# max32630 register map
Vendor: Maxim Integrated; Series: max3263x; File version: 1.2
CPU: CM4 r0p1, little endian, no MPU, FPU, 3 interrupt priority bits
Registers are 32-bit, read-write, reset 0x0 unless marked. A register's access mark holds for its fields unless they carry their own. Offsets are from the block's base; [hi:lo] are bit positions; {n}, {i} and the like mark numbered series; 'fields as' and 'values as' point back to an identical list.

## CLKMAN — System Clock Manager
Base 0x40000400
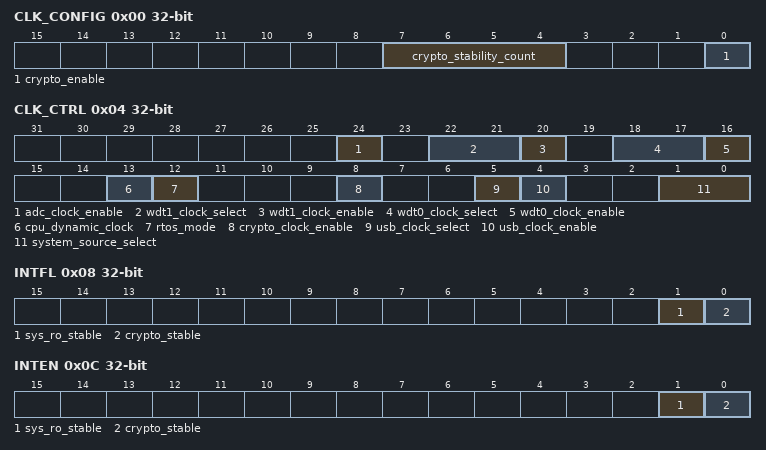
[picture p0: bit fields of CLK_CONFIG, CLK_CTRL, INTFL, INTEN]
0x00 CLK_CONFIG — System Clock Configuration
  [7:4] crypto_stability_count — Crypto Oscillator Stability Select
    0=2_EXP_8_CLOCKS (Clock is stable after 2^8 (256) clock cycles.); 1=2_EXP_9_CLOCKS (Clock is stable after 2^9 (512) clock cycles.); 2=2_EXP_10_CLOCKS (Clock is stable after 2^10 (1024) clock cycles.); 3=2_EXP_11_CLOCKS (Clock is stable after 2^11 (2048) clock cycles.); 4=2_EXP_12_CLOCKS (Clock is stable after 2^12 (4096) clock cycles.); 5=2_EXP_13_CLOCKS (Clock is stable after 2^13 (8192) clock cycles.); 6=2_EXP_14_CLOCKS (Clock is stable after 2^14 (16384) clock cycles.); 7=2_EXP_15_CLOCKS (Clock is stable after 2^15 (32768) clock cycles.); 8=2_EXP_16_CLOCKS (Clock is stable after 2^16 (65536) clock cycles.); 9=2_EXP_17_CLOCKS (Clock is stable after 2^17 (131072) clock cycles.); 10=2_EXP_18_CLOCKS (Clock is stable after 2^18 (262144) clock cycles.); 11=2_EXP_19_CLOCKS (Clock is stable after 2^19 (524288) clock cycles.); 12=2_EXP_20_CLOCKS (Clock is stable after 2^20 (1048576) clock cycles.); 13=2_EXP_21_CLOCKS (Clock is stable after 2^21 (2097152) clock cycles.); 14=2_EXP_22_CLOCKS (Clock is stable after 2^22 (4194304) clock cycles.); 15=2_EXP_23_CLOCKS (Clock is stable after 2^23 (8388608) clock cycles.)
  [0] crypto_enable — Cryptographic (TPU) Relaxation Oscillator Enable
0x04 CLK_CTRL — System Clock Controls
  [24] adc_clock_enable
  [22:21] wdt1_clock_select — Watchdog 1 Clock Source Select
    0=SCALED_SYS_CLK_CTRL_4_WDT1 (Selects scaled system clock source, as defined by SYS_CLK_CTRL_4_WDT1.); 1=32KHZ_RTC_OSCILLATOR (Selects output from 32.768kHz RTC oscillator.); 2=96MHZ_OSCILLATOR (Selects undivided 96MHz relaxation oscillator output.); 3=NANO_RING_OSCILLATOR (Selects nano-ring oscillator output.)
  [20] wdt1_clock_enable — Watchdog 1 Clock Enable
  [18:17] wdt0_clock_select — Watchdog 0 Clock Source Select
    0=SCALED_SYS_CLK_CTRL_4_WDT0 (Selects scaled system clock source, as defined by SYS_CLK_CTRL_4_WDT0.); 1=32KHZ_RTC_OSCILLATOR (Selects output from 32.768kHz RTC oscillator.); 2=96MHZ_OSCILLATOR (Selects undivided 96MHz relaxation oscillator output.); 3=NANO_RING_OSCILLATOR (Selects nano-ring oscillator output.)
  [16] wdt0_clock_enable — Watchdog 0 Clock Enable
  [13] cpu_dynamic_clock — Enable CPU Dynamic Clock Gating
  [12] rtos_mode — Enable RTOS Mode for SysTick Timers
  [8] crypto_clock_enable
  [5] usb_clock_select
  [4] usb_clock_enable
  [1:0] system_source_select — System Clock Source Select
    0=96MHZ_RO_DIV_2 (Selects 96MHz relaxation oscillator output divided by 2 (48MHz).); 1=96MHZ_RO (Selects undivided 96MHz relaxation oscillator output.)
0x08 INTFL — Interrupt Flags
  [1] sys_ro_stable write-1-clears — System Oscillator Stable Interrupt Flag
  [0] crypto_stable write-1-clears — Crypto Oscillator Stable Interrupt Flag
0x0C INTEN — Interrupt Enable/Disable Controls
  [1] sys_ro_stable — System Oscillator Stable Interrupt Enable
  [0] crypto_stable — Crypto Oscillator Stable Interrupt Enable
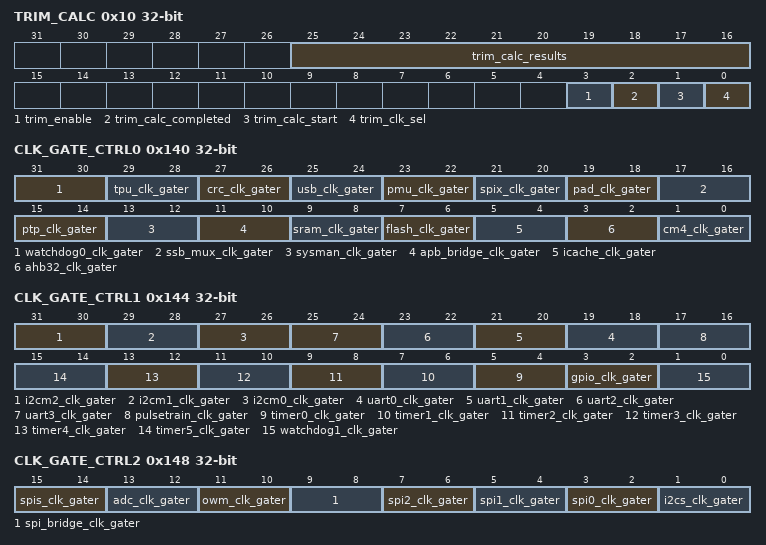
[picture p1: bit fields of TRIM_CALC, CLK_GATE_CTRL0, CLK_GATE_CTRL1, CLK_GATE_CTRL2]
0x10 TRIM_CALC — Trim Calculation Controls
  [25:16] trim_calc_results ro — Trim Calculation Results
  [3] trim_enable — Trim Logic Enable
  [2] trim_calc_completed ro — Trim Calculation Completed
  [1] trim_calc_start — Start Trim Calculation
  [0] trim_clk_sel — Trim Clock Select
0x14 I2C_TIMER_CTRL — I2C Timer Control
  [0] i2c_1ms_timer_en — I2C 1ms Timer Enable
0x18 CM4_START_CLK_EN0 — CM4 Start Clock on Interrupt Enable 0
  [31:0] ints — Interrupt Sources 0-31
0x1C CM4_START_CLK_EN1 — CM4 Start Clock on Interrupt Enable 1
  [31:0] ints — Interrupt Sources 32-63
0x20 CM4_START_CLK_EN2 — CM4 Start Clock on Interrupt Enable 2
  [31:0] ints — Interrupt Sources 95-64
0x40 SYS_CLK_CTRL_0_CM4 — Control Settings for CLK0 - Cortex M4 Clock
  [3:0] cm4_clk_scale
    0=DISABLED (Clock is disabled.); 1=DIV_1 (Clock frequency = (system clock source frequency) / 1.); 2=DIV_2 (Clock frequency = (system clock source frequency) / 2.); 3=DIV_4 (Clock frequency = (system clock source frequency) / 4.); 4=DIV_8 (Clock frequency = (system clock source frequency) / 8.); 5=DIV_16 (Clock frequency = (system clock source frequency) / 16.); 6=DIV_32 (Clock frequency = (system clock source frequency) / 32.); 7=DIV_64 (Clock frequency = (system clock source frequency) / 64.); 8=DIV_128 (Clock frequency = (system clock source frequency) / 128.); 9=DIV_256 (Clock frequency = (system clock source frequency) / 256.)
0x44 SYS_CLK_CTRL_1_SYNC — Control Settings for CLK1 - Synchronizer Clock
  [3:0] sync_clk_scale
    values as SYS_CLK_CTRL_0_CM4.cm4_clk_scale
0x48 SYS_CLK_CTRL_2_SPIX — Control Settings for CLK2 - SPI XIP Clock
  [3:0] spix_clk_scale
    values as SYS_CLK_CTRL_0_CM4.cm4_clk_scale
0x4C SYS_CLK_CTRL_3_PRNG — Control Settings for CLK3 - PRNG Clock
  [3:0] prng_clk_scale
    values as SYS_CLK_CTRL_0_CM4.cm4_clk_scale
0x50 SYS_CLK_CTRL_4_WDT0 — Control Settings for CLK4 - Watchdog Timer 0
  [3:0] watchdog0_clk_scale
    values as SYS_CLK_CTRL_0_CM4.cm4_clk_scale
0x54 SYS_CLK_CTRL_5_WDT1 — Control Settings for CLK5 - Watchdog Timer 1
  [3:0] watchdog1_clk_scale
    values as SYS_CLK_CTRL_0_CM4.cm4_clk_scale
0x58 SYS_CLK_CTRL_6_GPIO — Control Settings for CLK6 - Clock for GPIO Ports
  [3:0] gpio_clk_scale
    values as SYS_CLK_CTRL_0_CM4.cm4_clk_scale
0x5C SYS_CLK_CTRL_7_PT — Control Settings for CLK7 - Source Clock for All Pulse Trains
  [3:0] pulse_train_clk_scale
    values as SYS_CLK_CTRL_0_CM4.cm4_clk_scale
0x60 SYS_CLK_CTRL_8_UART — Control Settings for CLK8 - Source Clock for All UARTs
  [3:0] uart_clk_scale
    values as SYS_CLK_CTRL_0_CM4.cm4_clk_scale
0x64 SYS_CLK_CTRL_9_I2CM — Control Settings for CLK9 - Source Clock for All I2C Masters
  [3:0] i2cm_clk_scale
    values as SYS_CLK_CTRL_0_CM4.cm4_clk_scale
0x68 SYS_CLK_CTRL_10_I2CS — Control Settings for CLK10 - Source Clock for I2C Slave
  [3:0] i2cs_clk_scale
    values as SYS_CLK_CTRL_0_CM4.cm4_clk_scale
{0x40+4i} SYS_CLK_CTRL_{i}_SPI{i-11} (i=11..13) — Control Settings for CLK{i} - SPI Master {i-11}
  [3:0] spi{i-11}_clk_scale
    values as SYS_CLK_CTRL_0_CM4.cm4_clk_scale
0x78 SYS_CLK_CTRL_14_SPIB — Control Settings for CLK14 - SPI Bridge Clock
  [3:0] spib_clk_scale
    values as SYS_CLK_CTRL_0_CM4.cm4_clk_scale
0x7C SYS_CLK_CTRL_15_OWM — Control Settings for CLK15 - 1-Wire Master Clock
  [3:0] owm_clk_scale
    values as SYS_CLK_CTRL_0_CM4.cm4_clk_scale
0x80 SYS_CLK_CTRL_16_SPIS — Control Settings for CLK16 - SPI Slave Clock
  [3:0] spis_clk_scale
    values as SYS_CLK_CTRL_0_CM4.cm4_clk_scale
0x100 CRYPT_CLK_CTRL_0_AES — Control Settings for Crypto Clock 0 - AES
  [3:0] aes_clk_scale
    0=DISABLED (Clock is disabled.); 1=DIV_1 (Clock frequency = (cryptographic clock source frequency) / 1.); 2=DIV_2 (Clock frequency = (cryptographic clock source frequency) / 2.); 3=DIV_4 (Clock frequency = (cryptographic clock source frequency) / 4.); 4=DIV_8 (Clock frequency = (cryptographic clock source frequency) / 8.); 5=DIV_16 (Clock frequency = (cryptographic clock source frequency) / 16.); 6=DIV_32 (Clock frequency = (cryptographic clock source frequency) / 32.); 7=DIV_64 (Clock frequency = (cryptographic clock source frequency) / 64.); 8=DIV_128 (Clock frequency = (cryptographic clock source frequency) / 128.); 9=DIV_256 (Clock frequency = (cryptographic clock source frequency) / 256.)
0x104 CRYPT_CLK_CTRL_1_MAA — Control Settings for Crypto Clock 1 - MAA
  [3:0] maa_clk_scale
    values as CRYPT_CLK_CTRL_0_AES.aes_clk_scale
0x108 CRYPT_CLK_CTRL_2_PRNG — Control Settings for Crypto Clock 2 - PRNG
  [3:0] prng_clk_scale
    values as CRYPT_CLK_CTRL_0_AES.aes_clk_scale
0x140 CLK_GATE_CTRL0 — Dynamic Clock Gating Control Register 0
  [31:30] watchdog0_clk_gater — Clock Gating Control for Watchdog Timer 0
  [29:28] tpu_clk_gater — Clock Gating Control for TPU
  [27:26] crc_clk_gater — Clock Gating Control for CRC
  [25:24] usb_clk_gater — Clock Gating Control for USB
  [23:22] pmu_clk_gater — Clock Gating Control for PMU
  [21:20] spix_clk_gater — Clock Gating Control for SPI XIP
  [19:18] pad_clk_gater — Clock Gating Control for Pad Mode Filter
  [17:16] ssb_mux_clk_gater — Clock Gating Control for SSB Mux
  [15:14] ptp_clk_gater — Clock Gating Control for PTP Logic
  [13:12] sysman_clk_gater — Clock Gating Control for Clkman/Pwrman/IOman
  [11:10] apb_bridge_clk_gater — Clock Gating Control for AHB-to-APB Bridge
  [9:8] sram_clk_gater — Clock Gating Control for SRAM
  [7:6] flash_clk_gater — Clock Gating Control for Flash Memory
  [5:4] icache_clk_gater — Clock Gating Control for Instruction Cache
  [3:2] ahb32_clk_gater — Clock Gating Control for AHB32
  [1:0] cm4_clk_gater — Clock Gating Control for CM4 CPU
0x144 CLK_GATE_CTRL1 — Dynamic Clock Gating Control Register 1
  [31:30] i2cm2_clk_gater — Clock Gating Control for I2C Master 2
  [29:28] i2cm1_clk_gater — Clock Gating Control for I2C Master 1
  [27:26] i2cm0_clk_gater — Clock Gating Control for I2C Master 0
  [2n+19:2n+18] uart{n}_clk_gater (n=0..3) — Clock Gating Control for UART {n}
  [17:16] pulsetrain_clk_gater — Clock Gating Control for Pulse Train Generators
  [2n+5:2n+4] timer{n}_clk_gater (n=0..5) — Clock Gating Control for Timer/Counter Module {n}
  [3:2] gpio_clk_gater — Clock Gating Control for GPIO Ports
  [1:0] watchdog1_clk_gater — Clock Gating Control for Watchdog Timer 1
0x148 CLK_GATE_CTRL2 — Dynamic Clock Gating Control Register 2
  [15:14] spis_clk_gater — Clock Gating Control for SPI Slave
  [13:12] adc_clk_gater — Clock Gating Control for ADC
  [11:10] owm_clk_gater — Clock Gating Control for 1-Wire Master (OWM)
  [9:8] spi_bridge_clk_gater — Clock Gating Control for SPI Bridge
  [7:6] spi2_clk_gater — Clock Gating Control for SPI Master 2
  [5:4] spi1_clk_gater — Clock Gating Control for SPI Master 1
  [3:2] spi0_clk_gater — Clock Gating Control for SPI Master 0
  [1:0] i2cs_clk_gater — Clock Gating Control for I2C Slave
